AUTOSAR XML (schema 4-2-2)
package /ASW_Components
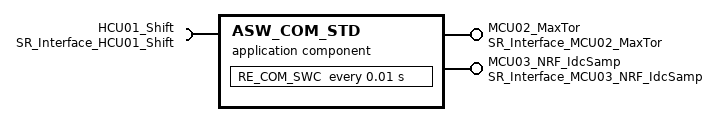
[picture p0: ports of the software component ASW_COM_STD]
  application sw component type ASW_COM_STD
    provide port MCU02_MaxTor: nonqueued-sender-com-spec{data-element=DE_MCU02_MaxTor, init-value=0}, provided-interface=SR_Interface_MCU02_MaxTor
    provide port MCU03_NRF_IdcSamp: nonqueued-sender-com-spec{data-element=DE_MCU03_NRF_IdcSamp, init-value=0}, provided-interface=SR_Interface_MCU03_NRF_IdcSamp
    require port HCU01_Shift: nonqueued-receiver-com-spec{data-element=DE_HCU01_Shift, alive-timeout=0.3, init-value=0}, required-interface=SR_Interface_HCU01_Shift
    behavior IB_ASW_COM_STD
      timing event TE_RE_COM_SWC_10ms: start-on-event=RE_COM_SWC, period=0.01
      runnable RE_COM_SWC
        data-read-access-points:
          access VA_Read_HCU01_Shift: accessed-variable=HCU01_Shift.DE_HCU01_Shift
        data-write-access-points:
          access VA_Write_MCU02_MaxTor: accessed-variable=MCU02_MaxTor.DE_MCU02_MaxTor
          access VA_Write_MCU03_NRF_IdcSamp: accessed-variable=MCU03_NRF_IdcSamp.DE_MCU03_NRF_IdcSamp
